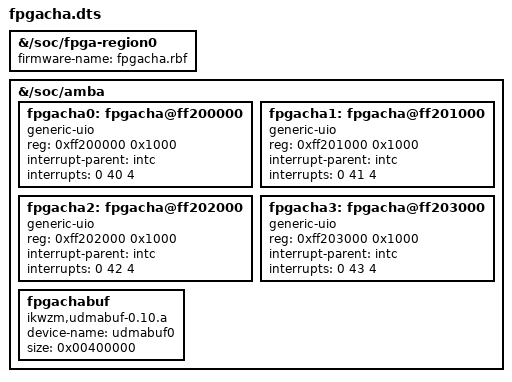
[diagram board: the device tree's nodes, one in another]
/dts-v1/;/plugin/;
/ {

    fragment@0 {
        target-path = "/soc/fpga-region0";
        __overlay__ {
            firmware-name = "fpgacha.rbf";
        };
    };
    fragment@1 {
        target-path = "/soc/amba";
        __overlay__ {
            #address-cells = <0x1>;
            #size-cells = <0x1>;
            
            fpgacha0: fpgacha@ff200000 {
                compatible = "generic-uio";
                reg = <0xff200000 0x1000>;
                interrupt-parent = <&intc>;
                interrupts = <0 40 4>;
            };

            fpgacha1: fpgacha@ff201000 {
                compatible = "generic-uio";
                reg = <0xff201000 0x1000>;
                interrupt-parent = <&intc>;
                interrupts = <0 41 4>;
            };
            
            fpgacha2: fpgacha@ff202000 {
                compatible = "generic-uio";
                reg = <0xff202000 0x1000>;
                interrupt-parent = <&intc>;
                interrupts = <0 42 4>;
            };
            
            fpgacha3: fpgacha@ff203000 {
                compatible = "generic-uio";
                reg = <0xff203000 0x1000>;
                interrupt-parent = <&intc>;
                interrupts = <0 43 4>;
            };
            
            fpgachabuf {
                compatible = "ikwzm,udmabuf-0.10.a";
                device-name = "udmabuf0";
                size = <0x00400000>;
            };
        };
    };
};

